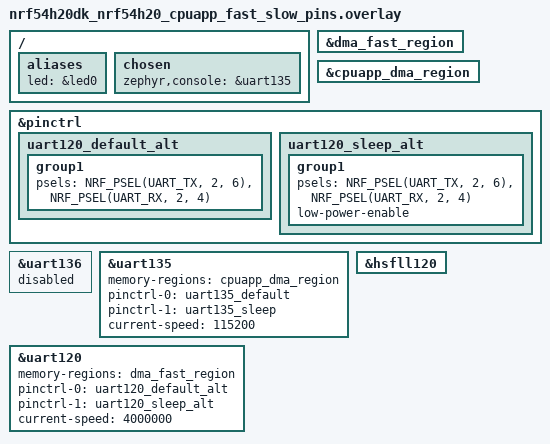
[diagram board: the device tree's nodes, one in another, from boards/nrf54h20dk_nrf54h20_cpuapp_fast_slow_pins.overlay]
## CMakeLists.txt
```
#
# Copyright (c) 2024 Nordic Semiconductor ASA
#
# SPDX-License-Identifier: LicenseRef-Nordic-5-Clause
#

cmake_minimum_required(VERSION 3.20.0)

find_package(Zephyr REQUIRED HINTS $ENV{ZEPHYR_BASE})

if(NOT SYSBUILD)
  message(FATAL_ERROR
    " This is a multi-image application that should be built using sysbuild.\n"
    " Add --sysbuild argument to west build command to prepare all the images."
  )
endif()

project(idle_uarte)

target_sources(app PRIVATE src/main.c)
```

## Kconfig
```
#
# Copyright (c) 2026 Nordic Semiconductor ASA
#
# SPDX-License-Identifier: LicenseRef-Nordic-5-Clause
#

config TEST_BAUDRATE_REGISTER_RETENTION
	bool "UARTE baudrate register retention test"

source "Kconfig.zephyr"
```

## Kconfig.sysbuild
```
#
# Copyright (c) 2024 Nordic Semiconductor ASA
#
# SPDX-License-Identifier: LicenseRef-Nordic-5-Clause
#

choice NETCORE
	default NETCORE_REMOTE_SLEEP_FOREVER

config NETCORE_REMOTE_SLEEP_FOREVER
	bool "Remote sleep forever image"

endchoice

config NETCORE_IMAGE_NAME
	default "remote_sleep_forever" if NETCORE_REMOTE_SLEEP_FOREVER

config NETCORE_IMAGE_PATH
	default "$(ZEPHYR_NRF_MODULE_DIR)/tests/benchmarks/power_consumption/common/remote_sleep_forever" if NETCORE_REMOTE_SLEEP_FOREVER

choice PPRCORE
	default PPRCORE_REMOTE_SLEEP_FOREVER if SOC_NRF9251_CPUAPP
	default PPRCORE_NONE

config PPRCORE_REMOTE_SLEEP_FOREVER
	bool "Remote sleep forever image"

endchoice

config PPRCORE_IMAGE_NAME
	default "remote_sleep_forever" if PPRCORE_REMOTE_SLEEP_FOREVER

config PPRCORE_IMAGE_PATH
	default "$(ZEPHYR_NRF_MODULE_DIR)/tests/benchmarks/power_consumption/common/remote_sleep_forever" if PPRCORE_REMOTE_SLEEP_FOREVER

source "share/sysbuild/Kconfig"
```

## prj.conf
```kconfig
CONFIG_SERIAL=y
CONFIG_MAIN_STACK_SIZE=2048
CONFIG_UART_ASYNC_API=y
CONFIG_UART_USE_RUNTIME_CONFIGURE=y

CONFIG_PM=y
CONFIG_PM_DEVICE=y
CONFIG_PM_DEVICE_RUNTIME=y
CONFIG_POWEROFF=y

CONFIG_BOOT_BANNER=n
CONFIG_NCS_BOOT_BANNER=n
CONFIG_ASSERT=y

# Enable for debugging purposes only
CONFIG_PRINTK=n
CONFIG_LOG=n
CONFIG_CONSOLE=n
CONFIG_UART_CONSOLE=n
```

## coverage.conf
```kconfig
CONFIG_SOC_NRF54H20_CPURAD_ENABLE=y
CONFIG_SERIAL=y
CONFIG_MAIN_STACK_SIZE=2048
CONFIG_UART_ASYNC_API=y
CONFIG_UART_USE_RUNTIME_CONFIGURE=y

CONFIG_PM=y
CONFIG_PM_DEVICE=y
CONFIG_PM_DEVICE_RUNTIME=y
CONFIG_POWEROFF=y

CONFIG_BOOT_BANNER=n
CONFIG_NCS_BOOT_BANNER=n
CONFIG_ASSERT=n
CONFIG_CLOCK_CONTROL=n

CONFIG_PRINTK=y
CONFIG_LOG=n
CONFIG_CONSOLE=y
CONFIG_UART_CONSOLE=y

CONFIG_LOG_BUFFER_SIZE=16384
```

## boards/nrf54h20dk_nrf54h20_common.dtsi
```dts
/*
 * Copyright (c) 2024 Nordic Semiconductor ASA
 *
 * SPDX-License-Identifier: LicenseRef-Nordic-5-Clause
 */

&cpuapp_dma_region {
	status="okay";
};

/* UART device used for test
 * not the default UART assignment for the LD
 */
&pinctrl {
	uart135_default_alt: uart135_default_alt {
		group1 {
			psels = <NRF_PSEL(UART_TX, 0, 6)>,
				<NRF_PSEL(UART_RX, 0, 7)>,
				<NRF_PSEL(UART_RTS, 0, 8)>,
				<NRF_PSEL(UART_CTS, 0, 9)>;
		};
	};

	uart135_sleep_alt: uart135_sleep_alt {
		group1 {
			psels = <NRF_PSEL(UART_TX, 0, 6)>,
				<NRF_PSEL(UART_RX, 0, 7)>,
				<NRF_PSEL(UART_RTS, 0, 8)>,
				<NRF_PSEL(UART_CTS, 0, 9)>;
			low-power-enable;
		};
	};
};

dut: &uart135 {
	status = "okay";
	memory-regions = <&cpuapp_dma_region>;
	pinctrl-0 = <&uart135_default_alt>;
	pinctrl-1 = <&uart135_sleep_alt>;
	pinctrl-names = "default", "sleep";
	current-speed = <115200>;
	hw-flow-control;
};
```

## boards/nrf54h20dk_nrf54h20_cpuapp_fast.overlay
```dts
/*
 * Copyright (c) 2024 Nordic Semiconductor ASA
 *
 * SPDX-License-Identifier: LicenseRef-Nordic-5-Clause
 */

/ {
	aliases {
		led = &led0;
		/delete-property/ led1;
	};
};

/delete-node/ &led1;

&dma_fast_region {
	status = "okay";
};

/* UART device used for test
 * not the default UART assignment for the LD
 */
&pinctrl {
	uart120_default_alt: uart120_default_alt {
		group1 {
			psels = <NRF_PSEL(UART_TX, 7, 7)>,
				<NRF_PSEL(UART_RX, 7, 4)>;
		};
	};

	uart120_sleep_alt: uart120_sleep_alt {
		group1 {
			psels = <NRF_PSEL(UART_TX, 7, 7)>,
				<NRF_PSEL(UART_RX, 7, 4)>;
			low-power-enable;
		};
	};
};

dut: &uart120 {
	status = "okay";
	memory-regions = <&dma_fast_region>;
	pinctrl-0 = <&uart120_default_alt>;
	pinctrl-1 = <&uart120_sleep_alt>;
	pinctrl-names = "default", "sleep";
	current-speed = <4000000>;
};

&hsfll120 {
	status = "okay";
};
```

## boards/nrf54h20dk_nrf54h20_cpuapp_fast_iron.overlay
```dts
/*
 * Copyright (c) 2024 Nordic Semiconductor ASA
 *
 * SPDX-License-Identifier: LicenseRef-Nordic-5-Clause
 */

/ {
	aliases {
		led = &led0;
		/delete-property/ led1;
	};
};

/delete-node/ &led1;

&dma_fast_region {
	status = "okay";
};

/* UART device used for test
 * not the default UART assignment for the LD
 */
&pinctrl {
	uart120_default_alt: uart120_default_alt {
		group1 {
			psels = <NRF_PSEL(UART_TX, 7, 7)>,
				<NRF_PSEL(UART_RX, 7, 4)>;
		};
	};

	uart120_sleep_alt: uart120_sleep_alt {
		group1 {
			psels = <NRF_PSEL(UART_TX, 7, 7)>,
				<NRF_PSEL(UART_RX, 7, 4)>;
			low-power-enable;
		};
	};
};

dut: &uart120 {
	status = "okay";
	memory-regions = <&dma_fast_region>;
	pinctrl-0 = <&uart120_default_alt>;
	pinctrl-1 = <&uart120_sleep_alt>;
	pinctrl-names = "default", "sleep";
	current-speed = <4000000>;
};
```

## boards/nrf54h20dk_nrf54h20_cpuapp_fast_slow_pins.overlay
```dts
/*
 * Copyright (c) 2024 Nordic Semiconductor ASA
 *
 * SPDX-License-Identifier: LicenseRef-Nordic-5-Clause
 */

/*
 * To execute this test case the following loopback
 * is required: P2.04 <--> P2.06
 * Note: Console UART is connected to P1 (if02)
 */

/ {
	aliases {
		led = &led0;
		/delete-property/ led1;
	};

	chosen {
		zephyr,console = &uart135;
	};
};

/delete-node/ &led1;

&dma_fast_region {
	status = "okay";
};

&cpuapp_dma_region {
	status = "okay";
};

&pinctrl {
	uart120_default_alt: uart120_default_alt {
		group1 {
			psels = <NRF_PSEL(UART_TX, 2, 6)>,
				<NRF_PSEL(UART_RX, 2, 4)>;
		};
	};

	uart120_sleep_alt: uart120_sleep_alt {
		group1 {
			psels = <NRF_PSEL(UART_TX, 2, 6)>,
				<NRF_PSEL(UART_RX, 2, 4)>;
			low-power-enable;
		};
	};
};

&uart136 {
	status = "disabled";
	/delete-property/ memory-regions;
};

&uart135 {
	status = "okay";
	memory-regions = <&cpuapp_dma_region>;
	pinctrl-0 = <&uart135_default>;
	pinctrl-1 = <&uart135_sleep>;
	pinctrl-names = "default", "sleep";
	current-speed = <115200>;
	/delete-property/ hw-flow-control;
};

dut: &uart120 {
	status = "okay";
	memory-regions = <&dma_fast_region>;
	pinctrl-0 = <&uart120_default_alt>;
	pinctrl-1 = <&uart120_sleep_alt>;
	pinctrl-names = "default", "sleep";
	current-speed = <4000000>;
	/delete-property/ hw-flow-control;
};

&hsfll120 {
	status = "okay";
};
```

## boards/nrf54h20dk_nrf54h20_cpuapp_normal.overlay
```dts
/*
 * Copyright (c) 2024 Nordic Semiconductor ASA
 *
 * SPDX-License-Identifier: LicenseRef-Nordic-5-Clause
 */

/ {
	aliases {
		led = &led0;
		/delete-property/ led1;
	};
};

/delete-node/ &led1;

&cpuapp_dma_region {
	status = "okay";
};

/* UART device used for test
 * not the default UART assignment for the LD
 */
&pinctrl {
	uart135_default_alt: uart135_default_alt {
		group1 {
			psels = <NRF_PSEL(UART_TX, 0, 6)>,
				<NRF_PSEL(UART_RX, 0, 7)>,
				<NRF_PSEL(UART_RTS, 0, 8)>,
				<NRF_PSEL(UART_CTS, 0, 9)>;
		};
	};

	uart135_sleep_alt: uart135_sleep_alt {
		group1 {
			psels = <NRF_PSEL(UART_TX, 0, 6)>,
				<NRF_PSEL(UART_RX, 0, 7)>,
				<NRF_PSEL(UART_RTS, 0, 8)>,
				<NRF_PSEL(UART_CTS, 0, 9)>;
			low-power-enable;
		};
	};
};

dut: &uart135 {
	status = "okay";
	memory-regions = <&cpuapp_dma_region>;
	pinctrl-0 = <&uart135_default_alt>;
	pinctrl-1 = <&uart135_sleep_alt>;
	pinctrl-names = "default", "sleep";
	current-speed = <115200>;
	hw-flow-control;
};
```

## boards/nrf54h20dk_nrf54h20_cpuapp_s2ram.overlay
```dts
/*
 * Copyright (c) 2024 Nordic Semiconductor ASA
 *
 * SPDX-License-Identifier: LicenseRef-Nordic-5-Clause
 */

#include "nrf54h20dk_nrf54h20_common.dtsi"

 / {
	power-states {
		idle: idle {
			compatible = "zephyr,power-state";
			power-state-name = "suspend-to-idle";
			min-residency-us = <100000>;
		};

		s2ram: s2ram {
			compatible = "zephyr,power-state";
			power-state-name = "suspend-to-ram";
			min-residency-us = <800000>;
		};
	};
};

&cpu {
	cpu-power-states = <&idle &s2ram>;
};
```

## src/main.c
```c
/*
 * Copyright (c) 2024 Nordic Semiconductor ASA
 *
 * SPDX-License-Identifier: LicenseRef-Nordic-5-Clause
 */

#include <zephyr/drivers/uart.h>
#include <nrfx_uarte.h>
#include <zephyr/pm/device.h>
#include <zephyr/pm/device_runtime.h>
#include <zephyr/kernel.h>
#include <zephyr/logging/log.h>
#include <zephyr/drivers/gpio.h>

/* Note: logging is normally disabled for this test
 * Enable only for debugging purposes
 */
LOG_MODULE_REGISTER(idle_uarte);

#define UARTE_GET_BAUDRATE(f_pclk, baudrate) ((BIT(20) / (f_pclk / baudrate)) << 12)

#if DT_NODE_EXISTS(DT_NODELABEL(dut))
#define UART_NODE DT_NODELABEL(dut)
#else
#error Improper device tree configuration, UARTE test node not available
#endif

#define TEST_BUFFER_LEN		 512
#define BAUDRATE_REG_VAL_ABS_TOL 2

static K_SEM_DEFINE(uart_rx_ready_sem, 0, 1);
static K_SEM_DEFINE(uart_tx_done_sem, 0, 1);

static const struct device *const uart_dev = DEVICE_DT_GET(UART_NODE);
static const struct device *const console_dev = DEVICE_DT_GET(DT_CHOSEN(zephyr_console));
static const struct gpio_dt_spec led = GPIO_DT_SPEC_GET(DT_ALIAS(led), gpios);
NRF_UARTE_Type *uarte_reg = (NRF_UARTE_Type *)DT_REG_ADDR(UART_NODE);

uint8_t test_pattern[TEST_BUFFER_LEN];
static uint8_t test_buffer[TEST_BUFFER_LEN];
static volatile uint8_t uart_error_counter;

void timer_handler(struct k_timer *dummy)
{
	k_sem_give(&uart_tx_done_sem);
}

K_TIMER_DEFINE(timer, timer_handler, NULL);

/*
 * Callback function for UART async transmission
 */
static void async_uart_callback(const struct device *dev, struct uart_event *evt, void *user_data)
{
	switch (evt->type) {
	case UART_TX_DONE:
		break;
	case UART_TX_ABORTED:
		printk("Callback should not enter here\n");
		__ASSERT_NO_MSG(1 == 0);
		break;
	case UART_RX_RDY:
		k_sem_give(&uart_rx_ready_sem);
		break;
	case UART_RX_BUF_RELEASED:
		break;
	case UART_RX_BUF_REQUEST:
		break;
	case UART_RX_DISABLED:
		break;
	default:
		break;
	}
}

/* Helper function for enabling UART RX */
void enable_uart_rx(void)
{
	int err;
	do {
		err = uart_rx_enable(uart_dev, test_buffer, TEST_BUFFER_LEN, 1000);
	} while (err == -EBUSY);
	__ASSERT(err == 0, "Unexpected error when enabling UART RX: %d", err);
}

void set_test_pattern(void)
{
	for (uint32_t counter = 0; counter < TEST_BUFFER_LEN; counter++) {
		test_pattern[counter] = (uint8_t)(counter & 0xFF);
	}
}

#if defined(CONFIG_TEST_BAUDRATE_REGISTER_RETENTION)
static void verify_uart_baudrate_register_retention(uint32_t baudrate)
{
	uint32_t baudrate_setting_from_reg, baudrate_setting_from_config;
	const uint32_t pclk_frequency = NRF_PERIPH_GET_FREQUENCY(UART_NODE);

	printk("UART PCLK frequency: %u\n", pclk_frequency);

	if (pclk_frequency > 16000000) {
		baudrate_setting_from_config = UARTE_GET_BAUDRATE(pclk_frequency, baudrate);
		baudrate_setting_from_reg = uarte_reg->BAUDRATE;

		printk("BAUDRATE register value read: %u\n", baudrate_setting_from_reg);
		printk("BAUDRATE register setting from config: %u\n", baudrate_setting_from_config);

		__ASSERT((baudrate_setting_from_reg <=
			  baudrate_setting_from_config + BAUDRATE_REG_VAL_ABS_TOL) &&
				 (baudrate_setting_from_reg >=
				  baudrate_setting_from_config - BAUDRATE_REG_VAL_ABS_TOL),
			 "BAUDRATE register value is invalid\n");
	} else {
		printk("BAUDRATE register setting is not verified for the slow instances\n");
	}
}
#endif /* CONFIG_TEST_BAUDRATE_REGISTER_RETENTION */

int main(void)
{
	int err;
	uint8_t switch_flag;
	uint32_t counter;
	struct uart_config test_uart_config;

	err = gpio_is_ready_dt(&led);
	__ASSERT(err, "Error: GPIO Device not ready");

	err = gpio_pin_configure_dt(&led, GPIO_OUTPUT_ACTIVE);
	__ASSERT(err == 0, "Could not configure led GPIO");

	printk("Hello World! %s\n", CONFIG_BOARD_TARGET);
	printk("UART instance: %s\n", uart_dev->name);
	set_test_pattern();
	err = uart_config_get(uart_dev, &test_uart_config);
	__ASSERT(err == 0, "Failed to get uart config");
	gpio_pin_set_dt(&led, 0);
	k_msleep(10);
	gpio_pin_set_dt(&led, 1);

	err = uart_configure(uart_dev, &test_uart_config);
	__ASSERT(err == 0, "Unexpected error when configuring UART: %d", err);

	/* UART is disabled so expect error. */
	err = uart_rx_disable(uart_dev);
	__ASSERT(err == -EFAULT, "Expected an error when disabling RX");

	err = uart_callback_set(uart_dev, async_uart_callback, NULL);
	__ASSERT(err == 0, "Unexpected error when setting callback %d", err);

	if (IS_ENABLED(CONFIG_PM_DEVICE_RUNTIME)) {
		pm_device_runtime_enable(uart_dev);
		pm_device_runtime_enable(console_dev);
	}

	counter = 0;
	while (1) {
		switch_flag = 1;
		k_timer_start(&timer, K_SECONDS(1), K_NO_WAIT);
		while (k_sem_take(&uart_tx_done_sem, K_NO_WAIT) != 0) {
			enable_uart_rx();
			do {
				err = uart_tx(uart_dev, test_pattern, TEST_BUFFER_LEN, 1000000);
			} while (err == -EBUSY);
			__ASSERT(err == 0, "Unexpected error when sending UART TX data: %d", err);
			while (k_sem_take(&uart_rx_ready_sem, K_NO_WAIT) != 0) {
			};

			for (int index = 0; index < TEST_BUFFER_LEN; index++) {
				__ASSERT(test_buffer[index] == test_pattern[index],
					 "Recieived data byte %d does not match pattern 0x%x != "
					 "0x%x",
					 index, test_buffer[index], test_pattern[index]);
			}
		}
		gpio_pin_set_dt(&led, 0);
		k_msleep(1000);
		gpio_pin_set_dt(&led, 1);

#if defined(CONFIG_TEST_BAUDRATE_REGISTER_RETENTION)
		verify_uart_baudrate_register_retention(test_uart_config.baudrate);
#endif

#if defined(CONFIG_COVERAGE)
		if (switch_flag) {
			printk("Coverage analysis start\n");
			break;
		}
#endif
	}
	return 0;
}
```
